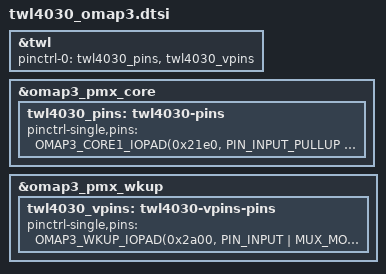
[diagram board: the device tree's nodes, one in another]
&twl {
	pinctrl-names = "default";
	pinctrl-0 = <&twl4030_pins &twl4030_vpins>;
};
&omap3_pmx_core {
	twl4030_pins: twl4030-pins {
		pinctrl-single,pins = <
			OMAP3_CORE1_IOPAD(0x21e0, PIN_INPUT_PULLUP | PIN_OFF_WAKEUPENABLE | MUX_MODE0)  
		>;
	};
};
&omap3_pmx_wkup {
	twl4030_vpins: twl4030-vpins-pins {
		pinctrl-single,pins = <
			OMAP3_WKUP_IOPAD(0x2a00, PIN_INPUT | MUX_MODE0)		 
			OMAP3_WKUP_IOPAD(0x2a02, PIN_INPUT | MUX_MODE0)		 
			OMAP3_WKUP_IOPAD(0x2a06, PIN_OUTPUT | MUX_MODE0)	 
			OMAP3_WKUP_IOPAD(0x2a18, PIN_OUTPUT | MUX_MODE0)	 
		>;
	};
};
